# AM13E23019 register map
Vendor: Texas Instruments; File version: 1.0
CPU: CM33 r0p1, little endian, MPU, FPU, VTOR, 4 interrupt priority bits
Registers are 32-bit, read-write, reset 0x0 unless marked. A register's access mark holds for its fields unless they carry their own. Offsets are from the block's base; [hi:lo] are bit positions; {n}, {i} and the like mark numbered series; 'fields as' and 'values as' point back to an identical list; <NAME> marks a mode.

## SYSCTL — SYSCTL module
Base 0x400AF000
0x1020 IIDX ro — SYSCTL interrupt index
  [2:0] STAT — The SYSCTL interrupt index (IIDX) register generates a value corresponding to the highest priority pending interrupt source. This value may be used as an address offset for fast, deterministic handling in the interrupt service routine. A read of the IIDX register will clear the corresponding interrupt status in the RIS and MIS registers.
    0=NO_INTR (No interrupt pending); 1=LFOSCGOOD (LFOSCGOOD interrupt pending); 2=ANACLKERR; 3=FLASHSEC; 4=SRAMSEC; 5=HFCLKGOOD; 6=SYSPLLGOOD; 7=HSCLKGOOD
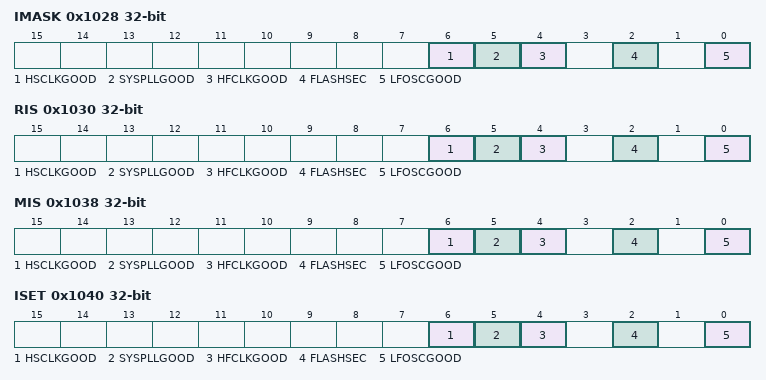
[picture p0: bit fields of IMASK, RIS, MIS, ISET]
0x1028 IMASK — SYSCTL interrupt mask
  [6] HSCLKGOOD
    0=DISABLE; 1=ENABLE
  [5] SYSPLLGOOD
    0=DISABLE; 1=ENABLE
  [4] HFCLKGOOD
    0=DISABLE; 1=ENABLE
  [2] FLASHSEC — Flash Single Error Correct
    0=DISABLE; 1=ENABLE
  [0] LFOSCGOOD — Enable or disable the LFOSCGOOD interrupt. LFOSCGOOD indicates that the LFOSC has started successfully.
    0=DISABLE (Interrupt disabled); 1=ENABLE (Interrupt enabled)
0x1030 RIS ro — SYSCTL raw interrupt status
  [6] HSCLKGOOD
    0=FALSE; 1=TRUE
  [5] SYSPLLGOOD
    0=FALSE; 1=TRUE
  [4] HFCLKGOOD
    0=FALSE; 1=TRUE
  [2] FLASHSEC — Flash Single Error Correct
    0=FALSE; 1=TRUE
  [0] LFOSCGOOD — Raw status of the LFOSCGOOD interrupt.
    0=FALSE (No interrupt pending); 1=TRUE (Interrupt pending)
0x1038 MIS ro — SYSCTL masked interrupt status
  [6] HSCLKGOOD
    0=FALSE; 1=TRUE
  [5] SYSPLLGOOD
    0=FALSE; 1=TRUE
  [4] HFCLKGOOD
    0=FALSE; 1=TRUE
  [2] FLASHSEC — Flash Single Error Correct
    0=FALSE; 1=TRUE
  [0] LFOSCGOOD — Masked status of the LFOSCGOOD interrupt.
    0=FALSE (No interrupt pending); 1=TRUE (Interrupt pending)
0x1040 ISET — SYSCTL interrupt set
  [6] HSCLKGOOD
    0=NO_EFFECT; 1=SET
  [5] SYSPLLGOOD
    0=NO_EFFECT; 1=SET
  [4] HFCLKGOOD
    0=NO_EFFECT; 1=SET
  [2] FLASHSEC — Flash Single Error Correct
    0=NO_EFFECT; 1=SET
  [0] LFOSCGOOD — Set the LFOSCGOOD interrupt.
    0=NO_EFFECT (Writing 0h has no effect); 1=SET (Set interrupt)
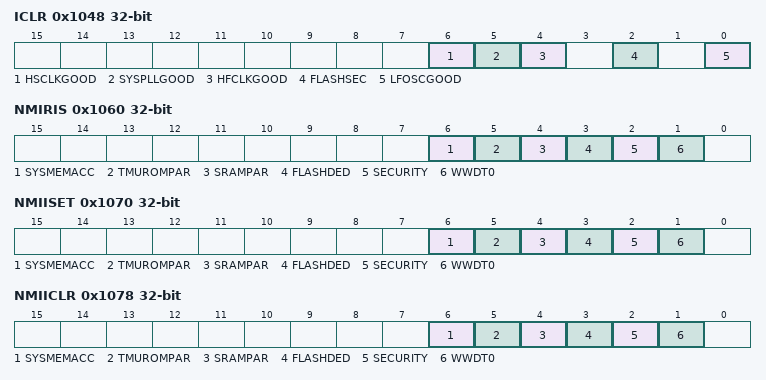
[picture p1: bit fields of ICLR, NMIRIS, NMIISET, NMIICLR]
0x1048 ICLR — SYSCTL interrupt clear
  [6] HSCLKGOOD
    0=NO_EFFECT; 1=CLR
  [5] SYSPLLGOOD
    0=NO_EFFECT; 1=CLR
  [4] HFCLKGOOD
    0=NO_EFFECT; 1=CLR
  [2] FLASHSEC — Flash Single Error Correct
    0=NO_EFFECT; 1=CLR
  [0] LFOSCGOOD — Clear the LFOSCGOOD interrupt.
    0=NO_EFFECT (Writing 0h has no effect); 1=CLR (Clear interrupt)
0x1050 NMIIIDX ro — NMI interrupt index
  [2:0] STAT — The NMI interrupt index (NMIIIDX) register generates a value corresponding to the highest priority pending NMI source. This value may be used as an address offset for fast, deterministic handling in the NMI service routine. A read of the NMIIIDX register will clear the corresponding interrupt status in the NMIRIS register.
    0=NO_INTR (No NMI pending); 1=BORLVL (Reserved); 2=WWDT0; 3=SECURITY; 4=FLASHDED; 5=SRAMPAR; 6=TMUROMPAR; 7=SYSMEMACC
0x1060 NMIRIS ro — NMI raw interrupt status
  [all] fields
    0=FALSE; 1=TRUE
  [6] SYSMEMACC — SYSMEM Access error
  [5] TMUROMPAR — TMU ROM Parity error
  [4] SRAMPAR — SRAM Parity Error Detect
  [3] FLASHDED — Flash Double Error Detect
  [2] SECURITY — Security Fault
  [1] WWDT0 — Watch Dog 0 Fault
0x1070 NMIISET — NMI interrupt set
  [all] fields
    0=NO_EFFECT; 1=SET
  [6] SYSMEMACC — SYSMEM Access error
  [5] TMUROMPAR — TMU ROM Parity error
  [4] SRAMPAR — SRAM Parity Error Detect
  [3] FLASHDED — Flash Double Error Detect
  [2] SECURITY — Security Fault
  [1] WWDT0 — Watch Dog 0 Fault
0x1078 NMIICLR — NMI interrupt clear
  [all] fields
    0=NO_EFFECT; 1=CLR
  [6] SYSMEMACC — SYSMEM Access error
  [5] TMUROMPAR — TMU ROM Parity error
  [4] SRAMPAR — SRAM Parity Error Detect
  [3] FLASHDED — Flash Double Error Detect
  [2] SECURITY — Security Fault
  [1] WWDT0 — Watch Dog 0 Fault
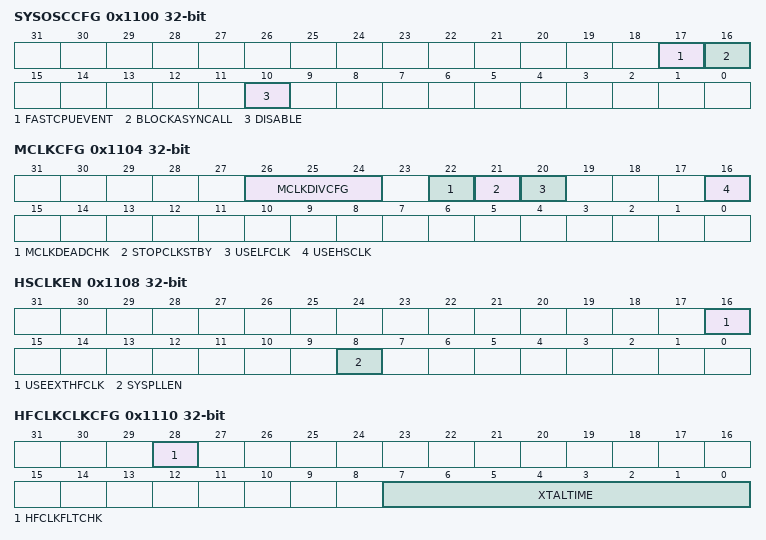
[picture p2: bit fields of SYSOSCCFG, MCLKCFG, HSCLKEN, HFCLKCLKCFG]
0x1100 SYSOSCCFG access per field — SYSOSC configuration
  [17] FASTCPUEVENT rw — if disabled CPU will not wakeup and continue in STANDBY
    0=DISABLE (An interrupt to the CPU will not assert a fast clock request); 1=ENABLE (An interrupt to the CPU will assert a fast clock request)
  [16] BLOCKASYNCALL rw — BLOCKASYNCALL may be used to mask block all asynchronous fast clock requests, preventing hardware from dynamically changing the active clock configuration when operating in a given mode.
    0=DISABLE (Asynchronous fast clock requests are controlled by the requesting peripheral); 1=ENABLE (All asynchronous fast clock requests are blocked)
  [10] DISABLE ro — DISABLE sets the SYSOSC enable/disable policy. SYSOSC may be powered off in RUN, SLEEP, and STOP modes to reduce power consumption. When SYSOSC is disabled, MCLK and ULPCLK are sourced from LFCLK.
    0=DISABLE (Do not disable SYSOSC); 1=ENABLE (Disable SYSOSC immediately and source MCLK and ULPCLK from LFCLK)
0x1104 MCLKCFG access per field — Main clock (MCLK) configuration
  [26:24] MCLKDIVCFG rw — MCLK Divider Configuration bits [1:0] are defined as MCLK4 is Bypass, MCLK2 is Bypass
    0=RATIO_1_1_1 (MCLK: No Divide, MCLK2: No Divide, MCLK4: No Divide); 1=RATIO_1_1_2 (MCLK: No Divide, MCLK2: No Divide, MCLK4: Divide MCLK by 2); 3=RATIO_1_1_4 (MCLK: No Divide, MCLK2: No Divide, MCLK4: Divide MCLK by 4); 5=RATIO_1_2_2 (MCLK: No Divide, MCLK2: Divide MCLK by 2, MCLK4: Divide MCLK by 2); 7=RATIO_1_2_4 (MCLK: No Divide, MCLK2: Divide MCLK by 2, MCLK4: MCLK by 4)
  [22] MCLKDEADCHK rw — MCLKDEADCHK enables or disables the continuous MCLK dead check monitor. LFCLK must be running before MCLKDEADCHK is enabled.
    0=DISABLE (The MCLK dead check monitor is disabled); 1=ENABLE (The MCLK dead check monitor is enabled)
  [21] STOPCLKSTBY rw — STOPCLKSTBY sets the STANDBY mode policy (STANDBY0 or STANDBY1). When set, ULPCLK and LFCLK are disabled to all peripherals in STANDBY mode, with the exception of TIMG0 and TIMG1 which continue to run. Wake-up is only possible via an asynchronous fast clock request.
    0=DISABLE (ULPCLK/LFCLK runs to all PD0 peripherals in STANDBY mode); 1=ENABLE (ULPCLK/LFCLK is disabled to all peripherals in STANDBY mode except TIMG0 and TIMG1)
  [20] USELFCLK ro — LFCLK is not an MCLK sourcei in PD1, tied 0.
    0=DISABLE (MCLK will not use the low frequency clock (LFCLK)); 1=ENABLE (MCLK will use the low frequency clock (LFCLK))
  [16] USEHSCLK rw — USEHSCLK, together with USELFCLK, sets the MCLK source policy. Set USEHSCLK to use HSCLK (HFCLK or SYSPLL) as the MCLK source in RUN and SLEEP modes.
    0=DISABLE (MCLK will not use the high speed clock (HSCLK)); 1=ENABLE (MCLK will use the high speed clock (HSCLK) in RUN and SLEEP mode)
0x1108 HSCLKEN — High-speed clock (HSCLK) source enable/disable
  [16] USEEXTHFCLK — USEEXTHFCLK selects the HFCLK_IN digital clock input to be the source for HFCLK.
    0=DISABLE (Use XTAL as the HFCLK source); 1=ENABLE (Use the HFCLK_IN digital clock input as the HFCLK source)
  [8] SYSPLLEN — SYSPLLEN enables or disables the system phase-lock loop (SYSPLL).
    0=DISABLE (Disable the SYSPLL); 1=ENABLE (Enable the SYSPLL)
0x110C HSCLKCFG — High-speed clock (HSCLK) source selection
  [0] HSCLKSEL — HSCLKSEL selects the HSCLK source (SYSPLL or HFCLK).
    0=SYSPLL (HSCLK is sourced from the SYSPLL); 1=HFCLKCLK (HSCLK is sourced from the HFCLK)
0x1110 HFCLKCLKCFG — High-frequency clock (HFCLK) configuration
  [28] HFCLKFLTCHK — HFCLKFLTCHK enables or disables the HFCLK startup monitor.
    0=DISABLE (HFCLK startup is not checked); 1=ENABLE (HFCLK startup is checked)
  [7:0] XTALTIME — XTALTIME specifies the XTAL startup time in 64us resolution. If the HFCLK startup monitor is enabled (HFCLKFLTCHK), XTAL will be checked after this time expires.
    0=MINSTARTTIME (Minimum startup time (approximatly zero)); 255=MAXSTARTTIME (Maximum startup time (approximatly 16.32ms))
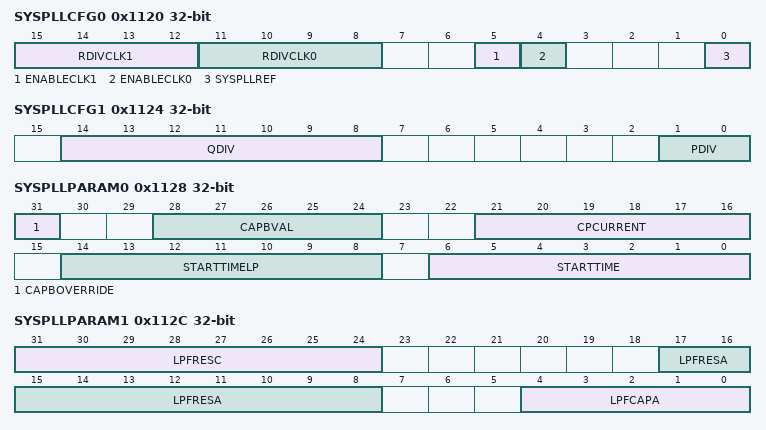
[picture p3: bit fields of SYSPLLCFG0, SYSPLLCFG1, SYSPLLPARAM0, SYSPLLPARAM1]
0x1120 SYSPLLCFG0 — SYSPLL reference and output configuration
  [15:12] RDIVCLK1 — RDIVCLK1 sets the final divider for the SYSPLLCLK1 output.
    0=CLK1DIV2 (SYSPLLCLK1 is divided by 2); 1=CLK1DIV4 (SYSPLLCLK1 is divided by 4); 2=CLK1DIV6 (SYSPLLCLK1 is divided by 6); 3=CLK1DIV8 (SYSPLLCLK1 is divided by 8); 4=CLK1DIV10 (SYSPLLCLK1 is divided by 10); 5=CLK1DIV12 (SYSPLLCLK1 is divided by 12); 6=CLK1DIV14 (SYSPLLCLK1 is divided by 14); 7=CLK1DIV16 (SYSPLLCLK1 is divided by 16); 8=CLK1DIV18 (SYSPLLCLK1 is divided by 18); 9=CLK1DIV20 (SYSPLLCLK1 is divided by 20); 10=CLK1DIV22 (SYSPLLCLK1 is divided by 22); 11=CLK1DIV24 (SYSPLLCLK1 is divided by 24); 12=CLK1DIV26 (SYSPLLCLK1 is divided by 26); 13=CLK1DIV28 (SYSPLLCLK1 is divided by 28); 14=CLK1DIV30 (SYSPLLCLK1 is divided by 30); 15=CLK1DIV32 (SYSPLLCLK1 is divided by 32)
  [11:8] RDIVCLK0 — RDIVCLK0 sets the final divider for the SYSPLLCLK0 output.
    0=CLK0DIV2 (SYSPLLCLK0 is divided by 2); 1=CLK0DIV4 (SYSPLLCLK0 is divided by 4); 2=CLK0DIV6 (SYSPLLCLK0 is divided by 6); 3=CLK0DIV8 (SYSPLLCLK0 is divided by 8); 4=CLK0DIV10 (SYSPLLCLK0 is divided by 10); 5=CLK0DIV12 (SYSPLLCLK0 is divided by 12); 6=CLK0DIV14 (SYSPLLCLK0 is divided by 14); 7=CLK0DIV16 (SYSPLLCLK0 is divided by 16); 8=CLK0DIV18 (SYSPLLCLK0 is divided by 18); 9=CLK0DIV20 (SYSPLLCLK0 is divided by 20); 10=CLK0DIV22 (SYSPLLCLK0 is divided by 22); 11=CLK0DIV24 (SYSPLLCLK0 is divided by 24); 12=CLK0DIV26 (SYSPLLCLK0 is divided by 26); 13=CLK0DIV28 (SYSPLLCLK0 is divided by 28); 14=CLK0DIV30 (SYSPLLCLK0 is divided by 30); 15=CLK0DIV32 (SYSPLLCLK0 is divided by 32)
  [5] ENABLECLK1 — ENABLECLK1 enables or disables the SYSPLLCLK1 output.
    0=DISABLE (SYSPLLCLK1 is disabled); 1=ENABLE (SYSPLLCLK1 is enabled)
  [4] ENABLECLK0 — ENABLECLK0 enables or disables the SYSPLLCLK0 output.
    0=DISABLE (SYSPLLCLK0 is disabled); 1=ENABLE (SYSPLLCLK0 is enabled)
  [0] SYSPLLREF — SYSPLLREF selects the system PLL (SYSPLL) reference clock source.
    0=SYSOSC (SYSPLL reference is SYSOSC); 1=HFCLK (SYSPLL reference is HFCLK)
0x1124 SYSPLLCFG1 — SYSPLL reference and feedback divider
  [14:8] QDIV — QDIV selects the SYSPLL feedback path divider.
    0=INVALID (Divide-by-one is not a valid QDIV option); 1=QDIVMIN (Feedback path is divided by 2); 126=QDIVMAX (Feedback path is divided by 127 (0x7E))
  [1:0] PDIV — PDIV selects the SYSPLL reference clock prescale divider.
    0=REFDIV1 (SYSPLLREF is not divided); 1=REFDIV2 (SYSPLLREF is divided by 2); 2=REFDIV4 (SYSPLLREF is divided by 4); 3=REFDIV8 (SYSPLLREF is divided by 8)
0x1128 SYSPLLPARAM0 — SYSPLL PARAM0 (load from FACTORY region)
  [31] CAPBOVERRIDE — CAPBOVERRIDE controls the override for Cap B
    0=DISABLE (Cap B override disabled); 1=ENABLE (Cap B override enabled)
  [28:24] CAPBVAL — Override value for Cap B
  [21:16] CPCURRENT — Charge pump current
  [14:8] STARTTIMELP — Startup time from low power mode exit to locked clock, in 1us resolution
  [6:0] STARTTIME — Startup time from enable to locked clock, in 1us resolution
0x112C SYSPLLPARAM1 — SYSPLL PARAM1 (load from FACTORY region)
  [31:24] LPFRESC — Loop filter Res C
  [17:8] LPFRESA — Loop filter Res A
  [4:0] LPFCAPA — Loop filter Cap A
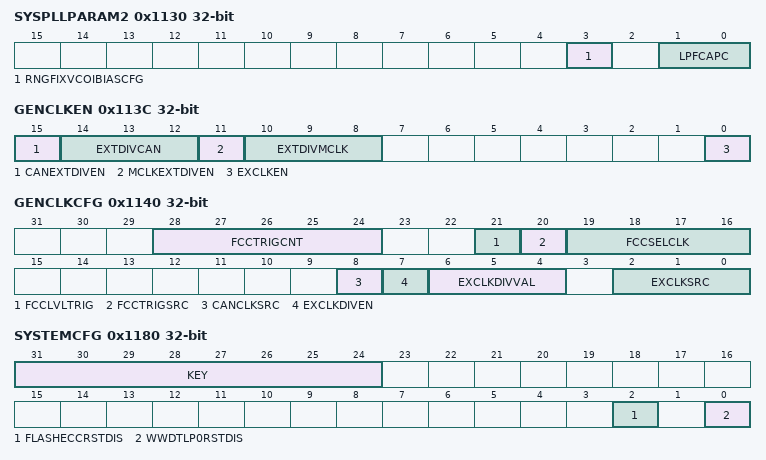
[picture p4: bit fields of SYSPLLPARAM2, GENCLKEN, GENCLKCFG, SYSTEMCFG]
0x1130 SYSPLLPARAM2 — SYSPLL PARAM2 (load from FACTORY region)
  [3] RNGFIXVCOIBIASCFG — 0 value for Temperature Compensation R addition
  [1:0] LPFCAPC — Loop filter Cap C
0x1134 SYSPLLLDOCTL — SYSPLL LDO CTL (load from FACTORY region)
  [15:0] LDOCTLLOWV — LDO Configurability
0x1138 SYSPLLLDOPROG — SYSPLL LDO VOUT PROG (load from FACTORY region)
  [2:0] LDOVOUTPROGLOWV — HPLL LDO Vout Prog
0x113C GENCLKEN — General clock enable control
  [15] CANEXTDIVEN — CANEXTDIVEN enables or disables the divider function of the PLL Source to CAN.
    0=PASSTHRU (CLock divider is disabled (passthrough, EXTDIVCAN is not applied)); 1=ENABLE (Clock divider is enabled (EXTDIVCAN is applied))
  [14:12] EXTDIVCAN — EXTDIVCAN selects the divider value for the divider for the PLL Source to CAN.
    0=DIV2 (CLK_OUT source is divided by 2); 1=DIV4 (CLK_OUT source is divided by 4); 2=DIV6 (CLK_OUT source is divided by 6); 3=DIV8 (CLK_OUT source is divided by 8); 4=DIV10 (CLK_OUT source is divided by 10); 5=DIV12 (CLK_OUT source is divided by 12); 6=DIV14 (CLK_OUT source is divided by 14); 7=DIV16 (CLK_OUT source is divided by 16)
  [11] MCLKEXTDIVEN — MCLKEXTDIVEN enables or disables the divider function of the PLL Source to MCLK.
    0=PASSTHRU (CLock divider is disabled (passthrough, EXTDIVMCLK is not applied)); 1=ENABLE (Clock divider is enabled (EXTDIVMCLK is applied))
  [10:8] EXTDIVMCLK — EXTDIVMCLK selects the divider value for the divider for the PLL Source MCLK.
    values as EXTDIVCAN
  [0] EXCLKEN — EXCLKEN enables the CLK_OUT external clock output block.
    0=DISABLE (CLK_OUT block is disabled); 1=ENABLE (CLK_OUT block is enabled)
0x1140 GENCLKCFG — General clock configuration
  [28:24] FCCTRIGCNT — FCCTRIGCNT specifies the number of trigger clock periods in the trigger window. FCCTRIGCNT=0h (one trigger clock period) up to 1Fh (32 trigger clock periods) may be specified.
  [21] FCCLVLTRIG — FCCLVLTRIG selects the frequency clock counter (FCC) trigger mode.
    0=RISE2RISE (Rising edge to rising edge triggered); 1=LEVEL (Level triggered)
  [20] FCCTRIGSRC — FCCTRIGSRC selects the frequency clock counter (FCC) trigger source.
    0=EXTPIN (FCC trigger is the external pin); 1=LFCLK (FCC trigger is the LFCLK)
  [19:16] FCCSELCLK — FCCSELCLK selectes the frequency clock counter (FCC) clock source.
    0=MCLKBY4 (FCC clock is MCLK/4); 1=SYSOSC (FCC clock is SYSOSC); 2=HFCLK (FCC clock is HFCLK); 3=EXTCLK (FCC clock is the CLK_OUT selection); 4=SYSPLLCLK0 (FCC clock is SYSPLLCLK0); 5=SYSPLLCLK1 (FCC clock is SYSPLLCLK1); 7=FCCIN (FCC clock is the FCCIN external input)
  [8] CANCLKSRC — CANCLKSRC selects the CANCLK source.
    0=HFCLK (CANCLK source is HFCLK); 1=SYSPLLOUT (CANCLK source is SYSPLLCLK)
  [7] EXCLKDIVEN — EXCLKDIVEN enables or disables the divider function of the CLK_OUT external clock output block.
    0=PASSTHRU (CLock divider is disabled (passthrough, EXCLKDIVVAL is not applied)); 1=ENABLE (Clock divider is enabled (EXCLKDIVVAL is applied))
  [6:4] EXCLKDIVVAL — EXCLKDIVVAL selects the divider value for the divider in the CLK_OUT external clock output block.
    values as GENCLKEN.EXTDIVCAN
  [2:0] EXCLKSRC — EXCLKSRC selects the source for the CLK_OUT external clock output block. ULPCLK and MFPCLK require the CLK_OUT divider (EXCLKDIVEN) to be enabled
    0=SYSOSC (CLK_OUT is SYSOSC); 1=ULPCLK (CLK_OUT is ULPCLK (EXCLKDIVEN must be enabled)); 2=LFCLK (CLK_OUT is LFCLK); 3=MFPCLK (CLK_OUT is MFPCLK (EXCLKDIVEN must be enabled)); 4=HFCLK (CLK_OUT is HFCLK); 5=SYSPLLOUT1 (CLK_OUT is SYSPLLCLK1 (SYSPLLCLK1 must be <=48MHz))
0x1144 PMODECFG — Power mode configuration
  [1:0] DSLEEP — DSLEEP selects the operating mode to enter upon a DEEPSLEEP request from the CPU.
    0=STOP (STOP mode is entered); 1=STANDBY (STANDBY mode is entered); 2=SHUTDOWN (SHUTDOWN mode is entered)
0x1148 MLDOLPENCFG — LDO Configuration Control
  [0] CVLODIS — Control to disable lowering the core voltage for STOP and STANDBY
    0=FALSE (Lower Core Voltage for STOP and STANDBY mode); 1=TRUE (Do Not Lower Core Voltage for STOP and STANDBY mode to provide faster wakeup)
0x1150 FCC ro — Frequency clock counter (FCC) count
  [21:0] DATA — Frequency clock counter (FCC) count value.
0x1154 PMULDOSPARECTL access not given — LDO Spare Control
0x1158 SYSCTL_ECO_REG1 access not given
0x115C SYSCTL_ECO_REG2 access not given
0x1180 SYSTEMCFG access per field — System configuration
  [31:24] KEY wo — Key which must be written for the write to take effect.
    27=KEY (Write key.)
  [2] FLASHECCRSTDIS rw — FLASHECCRSTDIS specifies whether a flash ECC double error detect (DED) will trigger a SYSRST or an NMI.
    0=FALSE (Flash ECC DED will trigger a SYSRST); 1=TRUE (Flash ECC DED will trigger a NMI)
  [0] WWDTLP0RSTDIS rw — WWDTLP0RSTDIS specifies whether a WWDT Error Event will trigger a BOOTRST or an NMI.
    0=FALSE (WWDTLP0 Error Event will trigger a BOOTRST); 1=TRUE (WWDTLP0 Error Event will trigger an NMI)
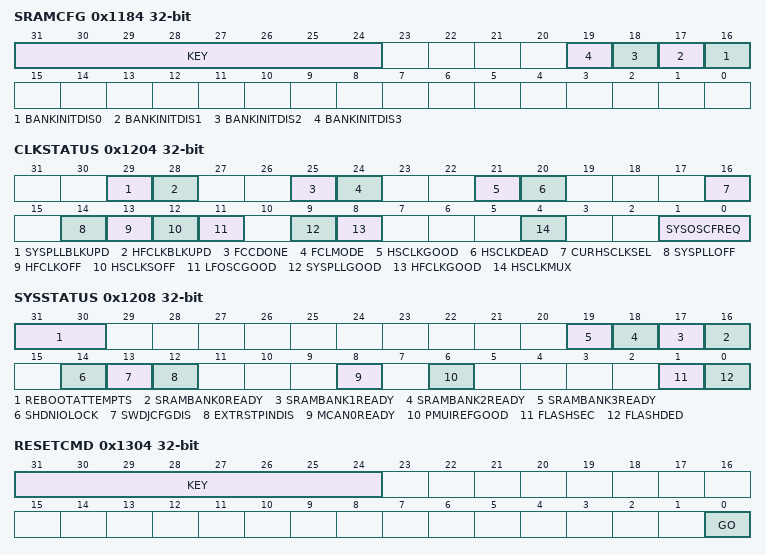
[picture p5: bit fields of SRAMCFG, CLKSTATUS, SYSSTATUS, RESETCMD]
0x1184 SRAMCFG access per field — System SRAM configuration
  [31:24] KEY wo — Key which must be written for the write to take effect.
    181=KEY (Write key.)
  [n+16] BANKINITDIS{n} rw (n=0..3) — SRAM BANK{n} Initialization
    0=FALSE (SRAM BANK{n} will Initialize when transitioning from OFF to ON); 1=TRUE (SRAM BANK{n} will NOT Initialize when transitioning from OFF to ON)
0x1200 WRITELOCK — SYSCTL register write lockout
  [0] ACTIVE — ACTIVE controls whether critical SYSCTL registers are write protected or not.
    0=DISABLE (Allow writes to lockable registers); 1=ENABLE (Disallow writes to lockable registers)
0x1204 CLKSTATUS ro — Clock module (CKM) status
  [29] SYSPLLBLKUPD — SYSPLLBLKUPD indicates when writes to SYSPLLCFG0/1 and SYSPLLPARAM0/1 are blocked.
    0=FALSE (writes to SYSPLLCFG0/1 and SYSPLLPARAM0/1 are allowed); 1=TRUE (writes to SYSPLLCFG0/1 and SYSPLLPARAM0/1 are blocked)
  [28] HFCLKBLKUPD — HFCLKBLKUPD indicates when writes to the HFCLKCLKCFG register are blocked.
    0=FALSE (Writes to HFCLKCLKCFG are allowed); 1=TRUE (Writes to HFCLKCLKCFG are blocked)
  [25] FCCDONE — FCCDONE indicates when a frequency clock counter capture is complete.
    0=NOTDONE (FCC capture is not done); 1=DONE (FCC capture is done)
  [24] FCLMODE — FCLMODE indicates if the SYSOSC frequency correction loop (FCL) is enabled.
    0=DISABLED (SYSOSC FCL is disabled); 1=ENABLED (SYSOSC FCL is enabled)
  [21] HSCLKGOOD — HSCLKGOOD is set by hardware if the selected clock source for HSCLK started successfully.
    0=FALSE (The HSCLK source did not start correctly); 1=TRUE (The HSCLK source started correctly)
  [20] HSCLKDEAD — HSCLKDEAD is set by hardware if the selected source for HSCLK was started but did not start successfully.
    0=FALSE (The HSCLK source was not started or started correctly); 1=TRUE (The HSCLK source did not start correctly)
  [16] CURHSCLKSEL — CURHSCLKSEL indicates the current clock source for HSCLK.
    0=SYSPLL (HSCLK is currently sourced from the SYSPLL); 1=HFCLK (HSCLK is currently sourced from the HFCLK)
  [14] SYSPLLOFF — SYSPLLOFF indicates if the SYSPLL is disabled or was dead at startup. When the SYSPLL is started, SYSPLLOFF is cleared by hardware. Following startup of the SYSPLL, if the SYSPLL startup monitor determines that the SYSPLL was not started correctly, SYSPLLOFF is set.
    0=FALSE (SYSPLL started correctly and is enabled); 1=TRUE (SYSPLL is disabled or was dead startup)
  [13] HFCLKOFF — HFCLKOFF indicates if the HFCLK is disabled or was dead at startup. When the HFCLK is started, HFCLKOFF is cleared by hardware. Following startup of the HFCLK, if the HFCLK startup monitor determines that the HFCLK was not started correctly, HFCLKOFF is set.
    0=FALSE (HFCLK started correctly and is enabled); 1=TRUE (HFCLK is disabled or was dead at startup)
  [12] HSCLKSOFF — HSCLKSOFF is set when the high speed clock sources (SYSPLL, HFCLK) are disabled or dead. It is the logical AND of HFCLKOFF and SYSPLLOFF.
    0=FALSE (SYSPLL, HFCLK, or both were started correctly and remain enabled); 1=TRUE (SYSPLL and HFCLK are both either off or dead)
  [11] LFOSCGOOD — LFOSCGOOD indicates when the LFOSC startup has completed and the LFOSC is ready for use.
    0=FALSE (LFOSC is not ready); 1=TRUE (LFOSC is ready)
  [9] SYSPLLGOOD — SYSPLLGOOD indicates if the SYSPLL started correctly. When the SYSPLL is started, SYSPLLGOOD is cleared by hardware. After the startup settling time has expired, the SYSPLL status is tested. If the SYSPLL started successfully the SYSPLLGOOD bit is set, else it is left cleared.
    0=FALSE (SYSPLL did not start correctly); 1=TRUE (SYSPLL started correctly)
  [8] HFCLKGOOD — HFCLKGOOD indicates that the HFCLK started correctly. When the XTAL is started or HFCLK_IN is selected as the HFCLK source, this bit will be set by hardware if a valid HFCLK is detected, and cleared if HFCLK is not operating within the expected range.
    0=FALSE (HFCLK did not start correctly); 1=TRUE (HFCLK started correctly)
  [4] HSCLKMUX — HSCLKMUX indicates if MCLK is currently sourced from the high-speed clock (HSCLK).
    0=SYSOSC (MCLK is not sourced from HSCLK); 1=HSCLK (MCLK is sourced from HSCLK)
  [1:0] SYSOSCFREQ — SYSOSCFREQ indicates the current SYSOSC operating frequency.
    0=SYSOSC32M (SYSOSC is at base frequency (32MHz)); 1=SYSOSC4M (SYSOSC is at low frequency (4MHz))
0x1208 SYSSTATUS ro — System status information
  [31:30] REBOOTATTEMPTS — REBOOTATTEMPTS indicates the number of boot attempts taken before the user application starts.
  [n+16] SRAMBANK{n}READY (n=0..3) — SRAM BANK{n} READY STATE
    0=FALSE (SRAM BANK{n} is NOT READY for access); 1=TRUE (SRAM BANK{n} is READY for access)
  [14] SHDNIOLOCK — SHDNIOLOCK indicates when IO is locked due to SHUTDOWN
    0=FALSE (IO IS NOT Locked due to SHUTDOWN); 1=TRUE (IO IS Locked due to SHUTDOWN)
  [13] SWDJCFGDIS — SWDJCFGDIS indicates when user has disabled the use of SWD/JTAG Port
    0=FALSE (SWD/JTAG Port Enabled); 1=TRUE (SWD/JTAG Port Disabled)
  [12] EXTRSTPINDIS — EXTRSTPINDIS indicates when user has disabled the use of external reset pin
    0=FALSE (External Reset Pin Enabled); 1=TRUE (External Reset Pin Disabled)
  [8] MCAN0READY — MCAN0READY indicates when the MCAN0 peripheral is ready.
    0=FALSE (MCAN0 is not ready); 1=TRUE (MCAN0 is ready)
  [6] PMUIREFGOOD — PMUIREFGOOD is set by hardware when the PMU current reference is ready.
    0=FALSE (IREF is not ready); 1=TRUE (IREF is ready)
  [1] FLASHSEC — FLASHSEC indicates if a flash ECC single bit error was detected and corrected (SEC).
    0=FALSE (No flash ECC single bit error detected); 1=TRUE (Flash ECC single bit error was detected and corrected)
  [0] FLASHDED — FLASHDED indicates if a flash ECC double bit error was detected (DED).
    0=FALSE (No flash ECC double bit error detected); 1=TRUE (Flash ECC double bit error detected)
0x1220 RSTCAUSE ro — Reset cause
  [4:0] ID — ID is a read-to-clear field which indicates the lowest level reset cause since the last read.
    0=NORST (No reset since last read); 1=PORHWFAIL (POR- violation, SHUTDNSTOREx or PMU trim parity fault); 2=POREXNRST (NRST triggered POR (>1s hold)); 3=PORSW (Software triggered POR); 4=BORSUPPLY (BOR0- violation); 5=BORWAKESHUTDN (SHUTDOWN mode exit); 8=BOOTNONPMUPARITY (Non-PMU trim parity fault); 9=BOOTCLKFAIL (Fatal clock failure); 12=BOOTEXNRST (NRST triggered BOOTRST (<1s hold)); 13=BOOTSW (Software triggered BOOTRST); 14=BOOTWWDT0 (WWDT0 violation); 16=SYSBSLEXIT (BSL exit); 17=SYSBSLENTRY (BSL entry); 20=SYSFLASHECC (Flash uncorrectable ECC error); 21=SYSCPULOCK (CPULOCK violation); 26=SYSDBG (Debug triggered SYSRST); 27=SYSSW (Software triggered SYSRST); 28=CPUDBG (Debug triggered CPURST); 29=CPUSW (Software triggered CPURST)
0x1300 RESETLEVEL — Reset level for application-triggered reset command
  [2:0] LEVEL — LEVEL is used to specify the type of reset to be issued when RESETCMD is set to generate a software triggered reset.
    0=SYS (Issue a SYSRST (CPU plus peripherals only)); 1=BOOT (Issue a BOOTRST (CPU, peripherals, and boot configuration routine)); 2=BOOTLOADERENTRY (Issue a SYSRST and enter the boot strap loader (BSL)); 3=POR (Issue a power-on reset (POR)); 4=BOOTLOADEREXIT (Issue a SYSRST and exit the boot strap loader (BSL))
0x1304 RESETCMD access per field — Execute an application-triggered reset command
  [31:24] KEY wo — Key which must be written for the write to take effect.
    228=KEY (Write key.)
  [0] GO rw — Execute the reset specified in RESETLEVEL.LEVEL. Must be written together with the KEY.
    1=TRUE (Issue reset)
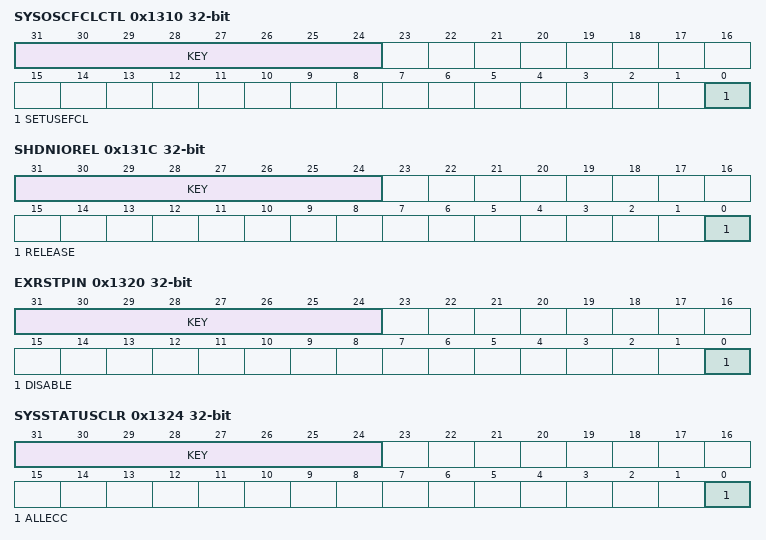
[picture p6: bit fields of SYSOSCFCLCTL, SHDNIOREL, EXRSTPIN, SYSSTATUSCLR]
0x1310 SYSOSCFCLCTL access per field — SYSOSC frequency correction loop (FCL) ROSC enable
  [31:24] KEY wo — Key which must be written for the write to take effect.
    42=KEY (Write key.)
  [0] SETUSEFCL rw — Set SETUSEFCL to enable the frequency correction loop in SYSOSC. Once enabled, this state is locked until the next BOOTRST.
    1=TRUE (Enable the SYSOSC FCL)
0x131C SHDNIOREL access per field — SHUTDOWN IO release control
  [31:24] KEY wo — Key which must be written for the write to take effect.
    145=KEY (Write key.)
  [0] RELEASE rw — Set RELEASE to release the IO after a SHUTDOWN mode exit.
    1=TRUE (Release IO)
0x1320 EXRSTPIN access per field — Disable the reset function of the NRST pin
  [31:24] KEY wo — Key which must be written for the write to take effect.
    30=KEY (Write key.)
  [0] DISABLE rw — Set DISABLE to disable the reset function of the NRST pin. Once set, this configuration is locked until the next POR.
    0=FALSE (Reset function of NRST pin is enabled); 1=TRUE (Reset function of NRST pin is disabled)
0x1324 SYSSTATUSCLR access per field — Clear sticky bits of SYSSTATUS
  [31:24] KEY wo — Key which must be written for the write to take effect.
    206=KEY (Write key.)
  [0] ALLECC rw — Set ALLECC to clear all ECC related SYSSTATUS indicators.
    1=CLEAR (Clear ECC error state)
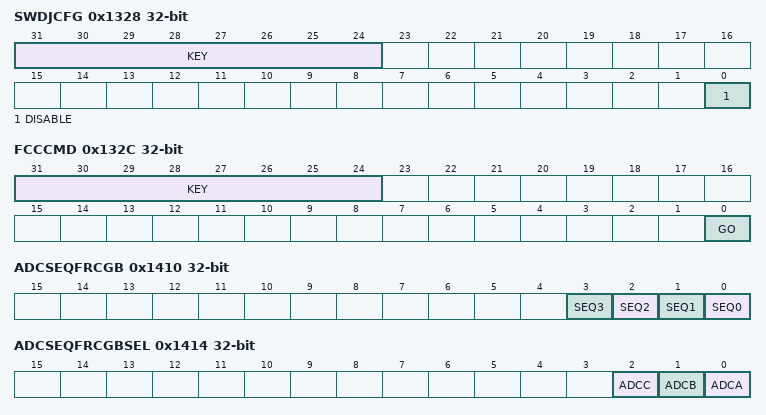
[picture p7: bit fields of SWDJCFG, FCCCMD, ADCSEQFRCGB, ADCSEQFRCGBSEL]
0x1328 SWDJCFG access per field — Disable the SWD/JTAG function on the SWD/JTAG pins
  [31:24] KEY wo — Key which must be written for the write to take effect.
    98=KEY (Write key.)
  [0] DISABLE rw — Set DISABLE to disable the SWD/JTAG function on SWD/JTAG pins, allowing the SWD/JTAG pins to be used as GPIO.
    1=TRUE (Disable SWD/JTAG function on SWD/JTAG pins)
0x132C FCCCMD access per field — Frequency clock counter start capture
  [31:24] KEY wo — Key which must be written for the write to take effect.
    14=KEY (Write key.)
  [0] GO rw — Set GO to start a capture with the frequency clock counter (FCC).
    1=TRUE
{0x1400+4i} SHUTDNSTORE{i} (i=0..3) — Shutdown storage memory (byte {i})
  [7:0] DATA — Shutdown storage byte {i}
0x1410 ADCSEQFRCGB — ADC Global Sequence Force
  [n] SEQ{n} (n=0..3) — Generate synchronous SW trigger for SEQ{n}
0x1414 ADCSEQFRCGBSEL — ADC Global Sequence Force Select
  [2] ADCC — Generate synchronous SW trigger for ADCC
  [1] ADCB — Generate synchronous SW trigger for ADCB
  [0] ADCA — Generate synchronous SW trigger for ADCA
0x1418 M33SPARESOCLOCK1 access not given — M33C1 Spare SOC LOCK Reg 1
0x141C M33SPARESOCLOCK2 access not given — M33C1 Spare SOC LOCK Reg 2
0x1420 SYSCTL_READ_REG access not given — Sysctl read only Reg
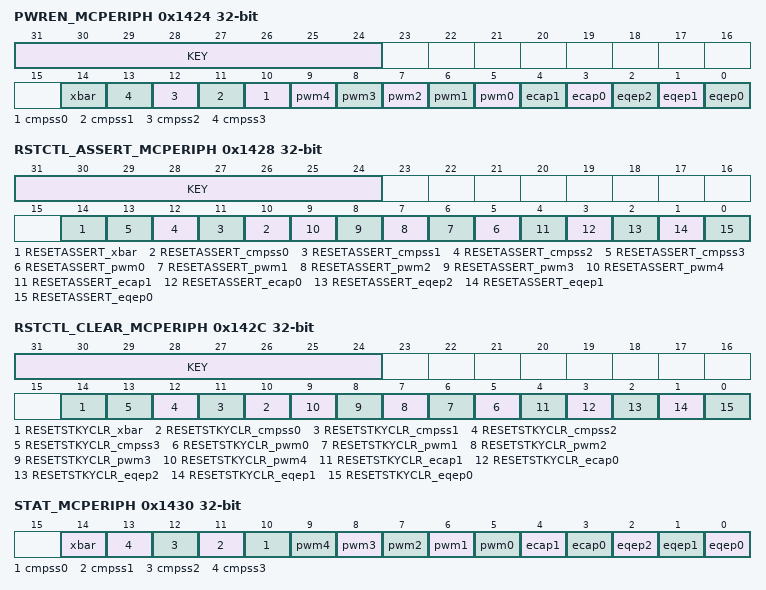
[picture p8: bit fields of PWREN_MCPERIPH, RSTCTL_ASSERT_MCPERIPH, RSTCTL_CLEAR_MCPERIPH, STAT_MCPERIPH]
0x1424 PWREN_MCPERIPH access per field — Register to control the power state
  [31:24] KEY wo — Key which must be written for the write to take effect.
    38=KEY (Write key.)
  [14] xbar rw — Enable the power to IP, KEY must be set to 26h to write to this bit
    0=Disable Power; 1=Enable Power
  [n+10] cmpss{n} rw (n=0..3) — Enable the power to IP, KEY must be set to 26h to write to this bit
    0=Disable Power; 1=Enable Power
  [n+5] pwm{n} rw (n=0..4) — Enable the power to IP, KEY must be set to 26h to write to this bit
    0=Disable Power; 1=Enable Power
  [4] ecap1 rw — Enable the power to IP, KEY must be set to 26h to write to this bit
    0=Disable Power; 1=Enable Power
  [3] ecap0 rw — Enable the power to IP, KEY must be set to 26h to write to this bit
    0=Disable Power; 1=Enable Power
  [2] eqep2 rw — Enable the power to IP, KEY must be set to 26h to write to this bit
    0=Disable Power; 1=Enable Power
  [1] eqep1 rw — Enable the power to IP, KEY must be set to 26h to write to this bit
    0=Disable Power; 1=Enable Power
  [0] eqep0 rw — Enable the power to IP, KEY must be set to 26h to write to this bit
    0=Disable Power; 1=Enable Power
0x1428 RSTCTL_ASSERT_MCPERIPH access per field — rstctl assert register to control reset assertion - Write Only Register, Always Read as 0
  [31:24] KEY wo — Key which must be written for the write to take effect.
    177=KEY (Write key.)
  [14] RESETASSERT_xbar rw — assert reset to the peripheral, KEY must be set to B1h to write to this bit
    0=no_effect (Writing 0 has no effect); 1=Assert reset
  [n+10] RESETASSERT_cmpss{n} rw (n=0..3) — assert reset to the peripheral, KEY must be set to B1h to write to this bit
    0=no_effect (Writing 0 has no effect); 1=Assert reset
  [n+5] RESETASSERT_pwm{n} rw (n=0..4) — assert reset to the peripheral, KEY must be set to B1h to write to this bit
    0=no_effect (Writing 0 has no effect); 1=Assert reset
  [4] RESETASSERT_ecap1 rw — assert reset to the peripheral, KEY must be set to B1h to write to this bit
    0=no_effect (Writing 0 has no effect); 1=Assert reset
  [3] RESETASSERT_ecap0 rw — assert reset to the peripheral, KEY must be set to B1h to write to this bit
    0=no_effect (Writing 0 has no effect); 1=Assert reset
  [2] RESETASSERT_eqep2 rw — assert reset to the peripheral, KEY must be set to B1h to write to this bit
    0=no_effect (Writing 0 has no effect); 1=Assert reset
  [1] RESETASSERT_eqep1 rw — assert reset to the peripheral, KEY must be set to B1h to write to this bit
    0=no_effect (Writing 0 has no effect); 1=Assert reset
  [0] RESETASSERT_eqep0 rw — assert reset to the peripheral, KEY must be set to B1h to write to this bit
    0=no_effect (Writing 0 has no effect); 1=Assert reset
0x142C RSTCTL_CLEAR_MCPERIPH access per field — rstctl clear register to control reset de-assertion - Write Only Register, Always Read as 0
  [31:24] KEY wo — Key which must be written for the write to take effect.
    177=KEY (Write key.)
  [14] RESETSTKYCLR_xbar rw — Clear the RESETSTKY bit in the STAT register, KEY must be set to B1h to write to this bit
    1=Clear reset sticky bit
  [n+10] RESETSTKYCLR_cmpss{n} rw (n=0..3) — Clear the RESETSTKY bit in the STAT register, KEY must be set to B1h to write to this bit
    1=Clear reset sticky bit
  [n+5] RESETSTKYCLR_pwm{n} rw (n=0..4) — Clear the RESETSTKY bit in the STAT register, KEY must be set to B1h to write to this bit
    1=Clear reset sticky bit
  [4] RESETSTKYCLR_ecap1 rw — Clear the RESETSTKY bit in the STAT register, KEY must be set to B1h to write to this bit
    1=Clear reset sticky bit
  [3] RESETSTKYCLR_ecap0 rw — Clear the RESETSTKY bit in the STAT register, KEY must be set to B1h to write to this bit
    1=Clear reset sticky bit
  [2] RESETSTKYCLR_eqep2 rw — Clear the RESETSTKY bit in the STAT register, KEY must be set to B1h to write to this bit
    1=Clear reset sticky bit
  [1] RESETSTKYCLR_eqep1 rw — Clear the RESETSTKY bit in the STAT register, KEY must be set to B1h to write to this bit
    1=Clear reset sticky bit
  [0] RESETSTKYCLR_eqep0 rw — Clear the RESETSTKY bit in the STAT register, KEY must be set to B1h to write to this bit
    1=Clear reset sticky bit
0x1430 STAT_MCPERIPH ro — IP State Register - Read Only
  [all] fields
    0=clr (The peripheral has not been reset since this bit was last cleared by RESETSTKYCLR in the RSTCTL register); 1=reset (The peripheral was reset since the last bit clear)
  [14] xbar — This bit indicates, if the peripheral was reset, since this bit was cleared by RESETSTKYCLR in the RSTCTL register
  [n+10] cmpss{n} (n=0..3) — This bit indicates, if the peripheral was reset, since this bit was cleared by RESETSTKYCLR in the RSTCTL register
  [n+5] pwm{n} (n=0..4) — This bit indicates, if the peripheral was reset, since this bit was cleared by RESETSTKYCLR in the RSTCTL register
  [4] ecap1 — This bit indicates, if the peripheral was reset, since this bit was cleared by RESETSTKYCLR in the RSTCTL register
  [3] ecap0 — This bit indicates, if the peripheral was reset, since this bit was cleared by RESETSTKYCLR in the RSTCTL register
  [2] eqep2 — This bit indicates, if the peripheral was reset, since this bit was cleared by RESETSTKYCLR in the RSTCTL register
  [1] eqep1 — This bit indicates, if the peripheral was reset, since this bit was cleared by RESETSTKYCLR in the RSTCTL register
  [0] eqep0 — This bit indicates, if the peripheral was reset, since this bit was cleared by RESETSTKYCLR in the RSTCTL register
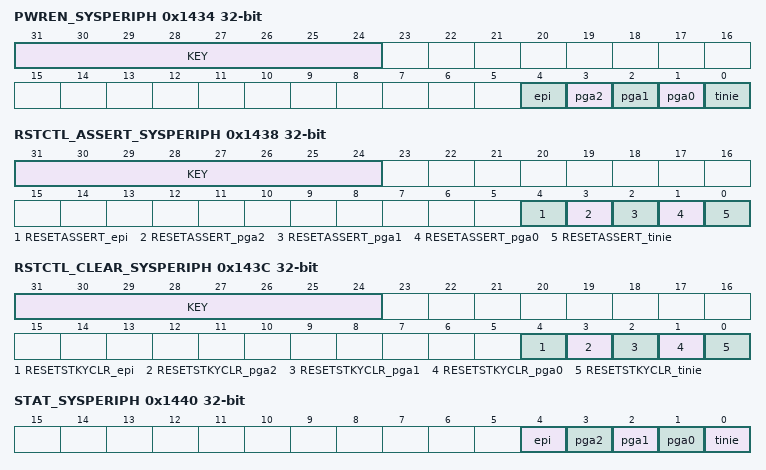
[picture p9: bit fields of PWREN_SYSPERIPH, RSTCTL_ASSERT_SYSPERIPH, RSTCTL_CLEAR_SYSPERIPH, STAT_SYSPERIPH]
0x1434 PWREN_SYSPERIPH access per field — Register to control the power state
  [31:24] KEY wo — Key which must be written for the write to take effect.
    38=KEY (Write key.)
  [4] epi rw — Enable the power to IP, KEY must be set to 26h to write to this bit
    0=Disable Power; 1=Enable Power
  [3] pga2 rw — Enable the power to IP, KEY must be set to 26h to write to this bit
    0=Disable Power; 1=Enable Power
  [2] pga1 rw — Enable the power to IP, KEY must be set to 26h to write to this bit
    0=Disable Power; 1=Enable Power
  [1] pga0 rw — Enable the power to IP, KEY must be set to 26h to write to this bit
    0=Disable Power; 1=Enable Power
  [0] tinie rw — Enable the power to IP, KEY must be set to 26h to write to this bit
    0=Disable Power; 1=Enable Power
0x1438 RSTCTL_ASSERT_SYSPERIPH access per field — rstcl assert Register - Write Only Register, Always Read as 0
  [31:24] KEY wo — Key which must be written for the write to take effect.
    177=KEY (Write key.)
  [4] RESETASSERT_epi rw — assert reset to the peripheral, KEY must be set to B1h to write to this bit
    0=no_effect (Writing 0 has no effect); 1=Assert reset
  [3] RESETASSERT_pga2 rw — assert reset to the peripheral, KEY must be set to B1h to write to this bit
    0=no_effect (Writing 0 has no effect); 1=Assert reset
  [2] RESETASSERT_pga1 rw — assert reset to the peripheral, KEY must be set to B1h to write to this bit
    0=no_effect (Writing 0 has no effect); 1=Assert reset
  [1] RESETASSERT_pga0 rw — assert reset to the peripheral, KEY must be set to B1h to write to this bit
    0=no_effect (Writing 0 has no effect); 1=Assert reset
  [0] RESETASSERT_tinie rw — assert reset to the peripheral, KEY must be set to B1h to write to this bit
    0=no_effect (Writing 0 has no effect); 1=Assert reset
0x143C RSTCTL_CLEAR_SYSPERIPH access per field — rstctl clear register to control reset de-assertion - Write Only Register, Always Read as 0
  [31:24] KEY wo — Key which must be written for the write to take effect.
    177=KEY (Write key.)
  [4] RESETSTKYCLR_epi rw — Clear the RESETSTKY bit in the STAT register, KEY must be set to B1h to write to this bit
    1=Clear reset sticky bit
  [3] RESETSTKYCLR_pga2 rw — Clear the RESETSTKY bit in the STAT register, KEY must be set to B1h to write to this bit
    1=Clear reset sticky bit
  [2] RESETSTKYCLR_pga1 rw — Clear the RESETSTKY bit in the STAT register, KEY must be set to B1h to write to this bit
    1=Clear reset sticky bit
  [1] RESETSTKYCLR_pga0 rw — Clear the RESETSTKY bit in the STAT register, KEY must be set to B1h to write to this bit
    1=Clear reset sticky bit
  [0] RESETSTKYCLR_tinie rw — Clear the RESETSTKY bit in the STAT register, KEY must be set to B1h to write to this bit
    1=Clear reset sticky bit
0x1440 STAT_SYSPERIPH ro — IP State Register - Read Only
  [all] fields
    values as the fields of STAT_MCPERIPH
  [4] epi — This bit indicates, if the peripheral was reset, since this bit was cleared by RESETSTKYCLR in the RSTCTL register
  [3] pga2 — This bit indicates, if the peripheral was reset, since this bit was cleared by RESETSTKYCLR in the RSTCTL register
  [2] pga1 — This bit indicates, if the peripheral was reset, since this bit was cleared by RESETSTKYCLR in the RSTCTL register
  [1] pga0 — This bit indicates, if the peripheral was reset, since this bit was cleared by RESETSTKYCLR in the RSTCTL register
  [0] tinie — This bit indicates, if the peripheral was reset, since this bit was cleared by RESETSTKYCLR in the RSTCTL register
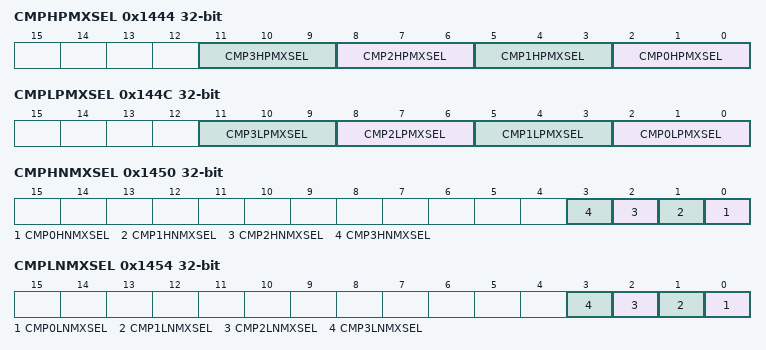
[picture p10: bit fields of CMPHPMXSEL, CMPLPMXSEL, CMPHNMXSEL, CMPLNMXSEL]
0x1444 CMPHPMXSEL — Bits to select one of the many sources on CompHP inputs. Refer to Pinmux diagram for details.
  [3n+2:3n] CMP{n}HPMXSEL (n=0..3) — CMP{n}HPMXSEL bits
0x144C CMPLPMXSEL — Bits to select one of the many sources on CompLP inputs. Refer to Pinmux diagram for details.
  [3n+2:3n] CMP{n}LPMXSEL (n=0..3) — CMP{n}LPMXSEL bits
0x1450 CMPHNMXSEL — Bits to select one of the many sources on CompHN inputs. Refer to Pinmux diagram for details.
  [n] CMP{n}HNMXSEL (n=0..3) — CMP{n}HNMXSEL bits
0x1454 CMPLNMXSEL — Bits to select one of the many sources on CompLN inputs. Refer to Pinmux diagram for details.
  [n] CMP{n}LNMXSEL (n=0..3) — CMP{n}LNMXSEL bits
0x1458 TSNSCFG access not given — Temperature Sensor Config Register
0x145C TSNSSCTL — Temperature Sensor Control Register
  [0] ENABLE — Temperature Sensor Enable
0x1460 PGACONFIG access not given — PGA Configuration Register
0x1464 REFCONFIGA access not given — Reference Configuration Regsiter
0x1468 INTERNALTESTCTL — Internal Test Node Control Register
  [5:0] TESTSEL — Test Select
    1=SEL1 (VDDCORE); 2=SEL2 (VDDA); 3=SEL3 (VSSA); 4=SEL4 (VREFLOAC); 5=SEL5 (CDAC1H); 6=SEL6 (CDAC1L); {v}=SEL{v} (CDAC2H) (v=7..12); 29=SEL14 (ENZ_CALIB_GAIN_3P3V will be made low. ADCA and ADCC will be in gain calibration mode, and 0.9xVREFHIAB pin voltage will be sampled by both ADCs through internal test-mux output); 30=SEL15 (CMPSS1 VDDA sense on TESTANA0,VSSA sense on TESTANA1); 31=SEL16 (ADCA VDDA sense on TESTANA0,VSSA sense on TESTANA1); 32=SEL17 (COMP DAC BUFFER VDDA sense on TESTANA0,VSSA sense on TESTANA1); 33=SEL18 (PGA1 VDDA sense on TESTANA0,VSSA sense on TESTANA1); 34=SEL19 (ADCCIO_TESTANA0_INT); 35=SEL20 (PMM/HPLL/INTOSC TESTANA0_INT); 36=SEL21 (ADCCIO_TESTANA1_INT); 37=SEL22 (PMM/HPLL/INTOSC TESTANA1_INT); 38=SEL23 (Enable resistor for I2V conversion. The same control enables the sampling of voltage across a resistor by ADC. R=2.5k, 38: R=10k, 39: R=35k); 41=SEL24 (USB_TESTANA0_INT); 42=SEL25 (USB_TESTANA1_INT); 43=SEL26 (USB_TESTANA0_INT & USB_TESTANA1_INT); 44=SEL27 (VSS); 45=SEL28 (Bring FLT3 & TESTPAD3 of flash on TESTANA1); 46=SEL29 (Enable resistor for I2V conversion. The same control enables the sampling of voltage across a resistor by ADC. R=2.5k, 47: R=10k, 48: R=35k); 49=SEL30 (VREFLOAC)
0x146C I2VCTL access not given — I2V Logic Control
0x1470 ADCDACLOOPBACK access not given — Not used in AM13
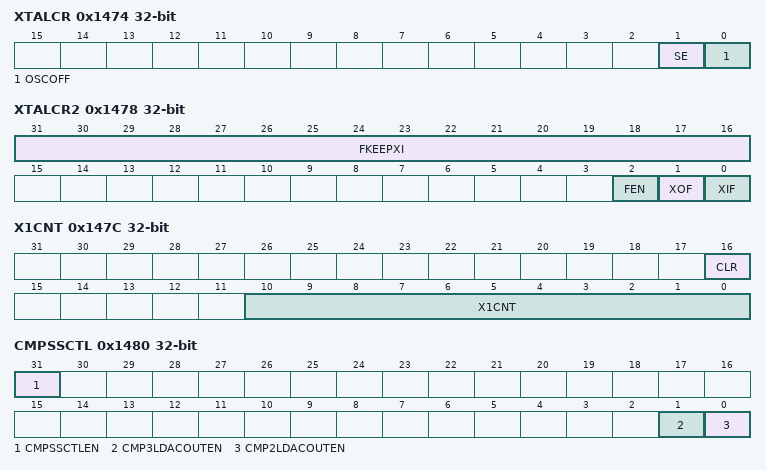
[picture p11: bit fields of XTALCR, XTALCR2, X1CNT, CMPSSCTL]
0x1474 XTALCR — XTAL Control Register
  [1] SE — XTAL Oscilator in Single-Ended
    0=FALSE (XTAL oscillator in Crystal mode); 1=TRUE (XTAL oscilator in single-ended mode (through X1))
  [0] OSCOFF — This bit if 1, powers-down the XTAL oscillator macro and hence doesnt let X2 to be driven by the XTAL oscillator. If a crystal is connected to X1/X2, user needs to first clear this bit, wait for the oscillator to power up (using X1CNT) and then only switch the clock source to X1/X2
    0=FALSE (XTAL Oscillator powered-up using X1/X2); 1=TRUE (XTAL Oscillator powered-down)
0x1478 XTALCR2 — XTAL Control Register for pad init
  [31:16] FKEEPXI — This field when written 0xface allows to hold the force value on XI as programmed on XIF. 0xface: Force on XI is continued as per XIF value regardless of XOSC ON/OFF state only in XTAL mode. In Single ended mode this field has no impact. Any other value: Force on XI is removed with enabling of XOSC as per FEN function.
  [2] FEN — XOSC pads initialisation enable. Configures XTAL oscillator pad initilisation. This register has effect only when XOSC is OFF (no SE , no XTAL mode). If this register is set during XOSC off state (XOSCOFF=1 & SE=0); then upon change of these controls this bit gets reset and rearmed
    0=FALSE (XOSC pads are not driven through GPIO connection.); 1=TRUE (XOSC pads are driven through connected GPIO as per XIF & XOF values.)
  [1] XOF — XO Initial value deposited before XOSC start. Polarity selection to initialise XO/X2 pad of the XOSC before start-up. This value shall be deposited on the pad before XOSC started (XOSCOFF=1). If FEN=0 or XOSC is in XTAL or SE mode; then this value will not be applied to the pad.
  [0] XIF — XI Initial value deposited before XOSC start. Polarity selection to initialise XI/X1 pad of the XOSC before start-up. This value shall be deposited on the pad before XOSC started (XOSCOFF=1). If FEN=0 or XOSC is in XTAL or SE mode; then this value will not be applied to the pad.
0x147C X1CNT access per field — x1cnt status register
  [16] CLR rw — X1 Counter clear: A write of 1 to this bit field clears the X1CNT and makes it count from 0x0 again (provided X1 clock is ticking). Writes of 0 are ignore to this bit field
  [10:0] X1CNT ro — This counter increments on every X1 CLOCKs positive-edge. Once it reaches the values of 0x7ff, it freezes. Before switching from SYSOSC/PLL clock to X1, application must check this counter and make sure that it has saturated. This will ensure that the Crystal connected to X1/X2 is oscillating
0x1480 CMPSSCTL — CMPSS control register
  [31] CMPSSCTLEN — Enable the CMPSSCTL Register
  [1] CMP3LDACOUTEN — Enable general purpose DAC functionality for CMPSS3 COMPDACL
  [0] CMP2LDACOUTEN — Enable general purpose DAC functionality for CMPSS2 COMPDACL
0x1484 CMPSSDACBUFCONFIG access not given — Config bits for CMPSS DAC buffer
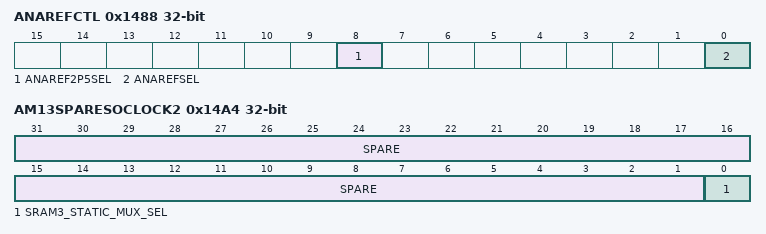
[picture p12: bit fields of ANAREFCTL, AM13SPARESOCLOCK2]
0x1488 ANAREFCTL — Analog Reference Select
  [8] ANAREF2P5SEL — Analog reference 2.5V source select. In internal reference mode, this bit selects which voltage the internal reference buffer drives onto the VREFHI pin. The buffer can drive either 1.65V onto the pin, resulting in a reference range of 0 to 3.3V, or the buffer can drive 2.5V onto the pin, resulting in a reference range of 0 to 2.5V. If switching between these two modes, the user must allow adequate time for the external capacitor to charge to the new voltage before using the ADC or buffered DAC. 0 - Internal 1.65V reference mode (3.3V reference range) 1 - Internal 2.5V reference mode (2.5V reference range)
  [0] ANAREFSEL — Analog reference mode select. This bit selects whether the VREFHI pin uses internal reference mode (the device drives a voltage onto the VREFHI pin) or external reference mode (the system is expected to drive a voltage into the VREFHI pin). 0 - Internal reference mode 1 - External reference mode
0x148C PERCLKCR — PWM Time Base Clock sync
  [0] TBCLKSYNC — PWM Time Base Clock sync: When set PWM time bases of all the PWM modules belonging to the same CPU-Subsystem (as partitioned using their CPUSEL bits) start counting
0x1490 ADC_MMR_OVRD_CTL access not given — ADC MMR Override control register for DFT: Control ADC enable override
0x1494 ADC_MMR_OVRD_VAL access not given — ADC MMR Override value register for DFT : Value of ADC enable override
0x1498 VREGCONFIGDEBUG access not given — VREG Configuration Debug Register
0x149C VREGCONFIGDFT access not given — VREG Configuration DFT Register
0x14A0 AM13SPAREIREFENSOCLOCK — AM13 Spare IREFEN SOC LOCK Reg
  [5:0] SPARE — Spare IREFEN SOC LOCK Register
0x14A4 AM13SPARESOCLOCK2 — AM13 Spare SOC LOCK Reg 2
  [31:1] SPARE — Spare SOC LOCK Register 2
  [0] SRAM3_STATIC_MUX_SEL — SRAM3 static mux select between CBUS and SBUS
    0=SBUS (SBUS path is selected); 1=CBUS (CBUS path is selected)
0x14A8 AM13SPARESOCLOCK3 access not given — AM13 Spare SOC LOCK Reg 3
0x14AC AM13SPARESOCLOCK4 access not given — AM13 Spare SOC LOCK Reg 4
